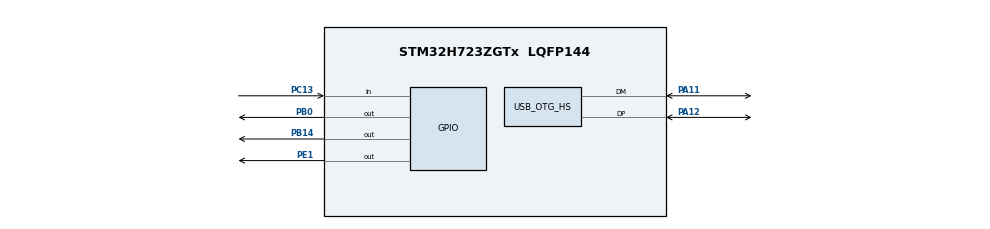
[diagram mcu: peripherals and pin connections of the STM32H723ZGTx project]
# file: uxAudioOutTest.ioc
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CORTEX_M7.AccessPermission_S-Cortex_Memory_Protection_Unit_Region2_Settings_S=MPU_REGION_FULL_ACCESS
CORTEX_M7.AccessPermission_S-Cortex_Memory_Protection_Unit_Region4_Settings_S=MPU_REGION_FULL_ACCESS
CORTEX_M7.AccessPermission_S-Cortex_Memory_Protection_Unit_Region5_Settings_S=MPU_REGION_FULL_ACCESS
CORTEX_M7.AccessPermission_S-Cortex_Memory_Protection_Unit_Region6_Settings_S=MPU_REGION_FULL_ACCESS
CORTEX_M7.BaseAddress_S-Cortex_Memory_Protection_Unit_Region2_Settings_S=0x24010000
CORTEX_M7.BaseAddress_S-Cortex_Memory_Protection_Unit_Region3_Settings_S=0x30000000
CORTEX_M7.BaseAddress_S-Cortex_Memory_Protection_Unit_Region4_Settings_S=0x38000000
CORTEX_M7.BaseAddress_S-Cortex_Memory_Protection_Unit_Region5_Settings_S=0x08000000
CORTEX_M7.BaseAddress_S-Cortex_Memory_Protection_Unit_Region6_Settings_S=0x40000000
CORTEX_M7.CPU_DCache=Enabled
CORTEX_M7.CPU_ICache=Enabled
CORTEX_M7.Enable_S-Cortex_Memory_Protection_Unit_Region1_Settings_S=__NULL
CORTEX_M7.Enable_S-Cortex_Memory_Protection_Unit_Region2_Settings_S=MPU_REGION_ENABLE
CORTEX_M7.Enable_S-Cortex_Memory_Protection_Unit_Region3_Settings_S=MPU_REGION_ENABLE
CORTEX_M7.Enable_S-Cortex_Memory_Protection_Unit_Region4_Settings_S=MPU_REGION_ENABLE
CORTEX_M7.Enable_S-Cortex_Memory_Protection_Unit_Region5_Settings_S=MPU_REGION_ENABLE
CORTEX_M7.Enable_S-Cortex_Memory_Protection_Unit_Region6_Settings_S=MPU_REGION_ENABLE
CORTEX_M7.IsBufferable_S-Cortex_Memory_Protection_Unit_Region6_Settings_S=MPU_ACCESS_BUFFERABLE
CORTEX_M7.IsCacheable_S-Cortex_Memory_Protection_Unit_Region5_Settings_S=MPU_ACCESS_CACHEABLE
CORTEX_M7.IsShareable_S-Cortex_Memory_Protection_Unit_Region2_Settings_S=MPU_ACCESS_NOT_SHAREABLE
CORTEX_M7.IsShareable_S-Cortex_Memory_Protection_Unit_Region3_Settings_S=MPU_ACCESS_SHAREABLE
CORTEX_M7.IsShareable_S-Cortex_Memory_Protection_Unit_Region4_Settings_S=MPU_ACCESS_SHAREABLE
CORTEX_M7.IsShareable_S-Cortex_Memory_Protection_Unit_Region6_Settings_S=MPU_ACCESS_SHAREABLE
CORTEX_M7.Size_S-Cortex_Memory_Protection_Unit_Region2_Settings_S=MPU_REGION_SIZE_64KB
CORTEX_M7.Size_S-Cortex_Memory_Protection_Unit_Region3_Settings_S=MPU_REGION_SIZE_32KB
CORTEX_M7.Size_S-Cortex_Memory_Protection_Unit_Region4_Settings_S=MPU_REGION_SIZE_16KB
CORTEX_M7.Size_S-Cortex_Memory_Protection_Unit_Region5_Settings_S=MPU_REGION_SIZE_1MB
CORTEX_M7.Size_S-Cortex_Memory_Protection_Unit_Region6_Settings_S=MPU_REGION_SIZE_512MB
CORTEX_M7.TypeExtField_S-Cortex_Memory_Protection_Unit_Region2_Settings_S=MPU_TEX_LEVEL1
CORTEX_M7.default_mode_Activation=1
Mcu.Family=STM32H7
Mcu.Name=STM32H723ZGTx
Mcu.Package=LQFP144
NUCLEO-H723ZG.BUTTON=1
NUCLEO-H723ZG.LD1=true
NUCLEO-H723ZG.LD2=true
NUCLEO-H723ZG.LD3=true
NUCLEO-H723ZG.VCP=true
NVIC.EXTI15_10_IRQn=true\:0\:0\:false\:false\:true\:false\:false\:true\:true
NVIC.OTG_HS_IRQn=true\:0\:0\:false\:false\:true\:false\:true\:true\:true
NVIC.PriorityGroup=NVIC_PRIORITYGROUP_4
NVIC.TIM1_UP_IRQn=true\:15\:0\:false\:false\:true\:false\:false\:true\:true
NVIC.TimeBase=TIM1_UP_IRQn
NVIC.TimeBaseIP=TIM1
PA11.Mode=Host_FS
PA11.Signal=USB_OTG_HS_DM
PA12.Mode=Host_FS
PA12.Signal=USB_OTG_HS_DP
PA13(JTMS/SWDIO).GPIO_Label=SWDIO
PA13(JTMS/SWDIO).Signal=DEBUG_JTMS-SWDIO
PA14(JTCK/SWCLK).GPIO_Label=SWCLK
PA14(JTCK/SWCLK).Signal=DEBUG_JTCK-SWCLK
PB0.Signal=GPIO_Output
PB14.Signal=GPIO_Output
PC13.Signal=GPIO_Input
PC14-OSC32_IN.Signal=RCC_OSC32_IN
PC15-OSC32_OUT.Signal=RCC_OSC32_OUT
PD8.Signal=USART3_TX
PD9.Signal=USART3_RX
PE1.Signal=GPIO_Output
PH0-OSC_IN.Mode=HSE-External-Clock-Source
PH0-OSC_IN.Signal=RCC_OSC_IN
ProjectManager.HeapSize=0x200
ProjectManager.StackSize=0x400
ProjectManager.TargetToolchain=CMake
RCC.ADCFreq_Value=76000000
RCC.APB1Freq_Value=137500000
RCC.APB2Freq_Value=137500000
RCC.APB3Freq_Value=137500000
RCC.APB4Freq_Value=137500000
RCC.CortexFreq_Value=550000000
RCC.D1PPRE=RCC_APB3_DIV2
RCC.D2PPRE1=RCC_APB1_DIV2
RCC.D2PPRE2=RCC_APB2_DIV2
RCC.D3PPRE=RCC_APB4_DIV2
RCC.DIVM1=1
RCC.DIVM2=1
RCC.DIVN1=68
RCC.DIVN2=19
RCC.DIVP1=1
RCC.DIVQ1=4
RCC.HCLKFreq_Value=275000000
RCC.HPRE=RCC_HCLK_DIV2
RCC.HSE_VALUE=8000000
RCC.PLLFRACN=6144
RCC.PLLSourceVirtual=RCC_PLLSOURCE_HSE
RCC.SYSCLKFreq_VALUE=550000000
RCC.SYSCLKSource=RCC_SYSCLKSOURCE_PLLCLK
RCC.USBCLockSelection=RCC_USBCLKSOURCE_HSI48
RCC.USBFreq_Value=48000000
STMicroelectronics.X-CUBE-AZRTOS-H7.3.4.0.REG_UX_HOST_CORE=true
STMicroelectronics.X-CUBE-AZRTOS-H7.3.4.0.REG_UX_Host_THREAD=1
STMicroelectronics.X-CUBE-AZRTOS-H7.3.4.0.TX_APP_CREATION=1
STMicroelectronics.X-CUBE-AZRTOS-H7.3.4.0.TX_APP_GENERATE_INIT_CODE=true
STMicroelectronics.X-CUBE-AZRTOS-H7.3.4.0.TX_APP_MEM_POOL_SIZE=40*1024
STMicroelectronics.X-CUBE-AZRTOS-H7.3.4.0.TX_APP_STACK_SIZE=1024
STMicroelectronics.X-CUBE-AZRTOS-H7.3.4.0.ThreadXCcRTOSJjThreadXJjCore=true
STMicroelectronics.X-CUBE-AZRTOS-H7.3.4.0.USBXCcUSBJjUSBXJjCoreSystem=true
STMicroelectronics.X-CUBE-AZRTOS-H7.3.4.0.USBXCcUSBJjUSBXJjUXOoHostOoClassOoAUDIO=true
STMicroelectronics.X-CUBE-AZRTOS-H7.3.4.0.USBXCcUSBJjUSBXJjUXOoHostOoControllers=true
STMicroelectronics.X-CUBE-AZRTOS-H7.3.4.0.USBXCcUSBJjUSBXJjUXOoHostOoCoreStack=true
STMicroelectronics.X-CUBE-AZRTOS-H7.3.4.0.USBX_HOST_SYS_SIZE=20*1024
STMicroelectronics.X-CUBE-AZRTOS-H7.3.4.0.UX_HOST_APP_MEM_POOL_SIZE=32*1024
STMicroelectronics.X-CUBE-AZRTOS-H7.3.4.0.UX_HOST_CLASS_AUDIO_2_SUPPORT=1
STMicroelectronics.X-CUBE-AZRTOS-H7.3.4.0.UX_HOST_CLASS_AUDIO_FEEDBACK_SUPPORT=1
STMicroelectronics.X-CUBE-AZRTOS-H7.3.4.0.UX_MAX_HCD=2
STMicroelectronics.X-CUBE-AZRTOS-H7.3.4.0_IsAnAzureRtosMw=true
USB_OTG_HS.VirtualMode-Host_FS=Host_FS
USB_OTG_HS.dma_enable-Host_FS=ENABLE
VP_MEMORYMAP_VS_MEMORYMAP.Mode=CurAppReg
VP_NUCLEO-H723ZG_VS_BSP_COMMON.Mode=COMMON
VP_STMicroelectronics.X-CUBE-AZRTOS-H7_VS_RTOSJjThreadX_6.4.0_3.4.0.Mode=RTOSJjThreadX
VP_STMicroelectronics.X-CUBE-AZRTOS-H7_VS_USBJjUSBX_6.4.0_3.4.0.Mode=USBJjUSBX
VP_SYS_VS_tim1.Mode=TIM1
board=NUCLEO-H723ZG

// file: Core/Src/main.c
/* USER CODE BEGIN Header */
/**
  ******************************************************************************
  * @file           : main.c
  * @brief          : Main program body
  ******************************************************************************
  * @attention
  *
  * Copyright (c) 2025 STMicroelectronics.
  * All rights reserved.
  *
  * This software is licensed under terms that can be found in the LICENSE file
  * in the root directory of this software component.
  * If no LICENSE file comes with this software, it is provided AS-IS.
  *
  ******************************************************************************
  */
/* USER CODE END Header */
#include "app_threadx.h"
#include "main.h"
#include "gpio.h"

COM_InitTypeDef BspCOMInit;

void SystemClock_Config(void);
static void MPU_Config(void);

int main(void)
{

  /* MPU Configuration--------------------------------------------------------*/
  MPU_Config();

  /* Enable the CPU Cache */

  /* Enable I-Cache---------------------------------------------------------*/
  SCB_EnableICache();

  /* Enable D-Cache---------------------------------------------------------*/
  SCB_EnableDCache();

  /* MCU Configuration--------------------------------------------------------*/

  /* Reset of all peripherals, Initializes the Flash interface and the Systick. */
  HAL_Init();

  /* Configure the system clock */
  SystemClock_Config();

  /* Initialize all configured peripherals */
  MX_GPIO_Init();

  /* Initialize leds */
  BSP_LED_Init(LED_GREEN);
  BSP_LED_Init(LED_YELLOW);
  BSP_LED_Init(LED_RED);

  /* Initialize USER push-button, will be used to trigger an interrupt each time it's pressed.*/
  BSP_PB_Init(BUTTON_USER, BUTTON_MODE_EXTI);

  /* Initialize COM1 port (115200, 8 bits (7-bit data + 1 stop bit), no parity */
  BspCOMInit.BaudRate   = 115200;
  BspCOMInit.WordLength = COM_WORDLENGTH_8B;
  BspCOMInit.StopBits   = COM_STOPBITS_1;
  BspCOMInit.Parity     = COM_PARITY_NONE;
  BspCOMInit.HwFlowCtl  = COM_HWCONTROL_NONE;
  if (BSP_COM_Init(COM1, &BspCOMInit) != BSP_ERROR_NONE)
  {
    Error_Handler();
  }

  MX_ThreadX_Init();

  /* We should never get here as control is now taken by the scheduler */

  /* Infinite loop */
  while (1)
  {

  }
}

void SystemClock_Config(void)
{
  RCC_OscInitTypeDef RCC_OscInitStruct = {0};
  RCC_ClkInitTypeDef RCC_ClkInitStruct = {0};

  /** Supply configuration update enable
  */
  HAL_PWREx_ConfigSupply(PWR_LDO_SUPPLY);

  /** Configure the main internal regulator output voltage
  */
  __HAL_PWR_VOLTAGESCALING_CONFIG(PWR_REGULATOR_VOLTAGE_SCALE0);

  while(!__HAL_PWR_GET_FLAG(PWR_FLAG_VOSRDY)) {}

  /** Initializes the RCC Oscillators according to the specified parameters
  * in the RCC_OscInitTypeDef structure.
  */
  RCC_OscInitStruct.OscillatorType = RCC_OSCILLATORTYPE_HSI48|RCC_OSCILLATORTYPE_HSE;
  RCC_OscInitStruct.HSEState = RCC_HSE_BYPASS;
  RCC_OscInitStruct.HSI48State = RCC_HSI48_ON;
  RCC_OscInitStruct.PLL.PLLState = RCC_PLL_ON;
  RCC_OscInitStruct.PLL.PLLSource = RCC_PLLSOURCE_HSE;
  RCC_OscInitStruct.PLL.PLLM = 1;
  RCC_OscInitStruct.PLL.PLLN = 68;
  RCC_OscInitStruct.PLL.PLLP = 1;
  RCC_OscInitStruct.PLL.PLLQ = 4;
  RCC_OscInitStruct.PLL.PLLR = 2;
  RCC_OscInitStruct.PLL.PLLRGE = RCC_PLL1VCIRANGE_3;
  RCC_OscInitStruct.PLL.PLLVCOSEL = RCC_PLL1VCOWIDE;
  RCC_OscInitStruct.PLL.PLLFRACN = 6144;
  if (HAL_RCC_OscConfig(&RCC_OscInitStruct) != HAL_OK)
  {
    Error_Handler();
  }

  /** Initializes the CPU, AHB and APB buses clocks
  */
  RCC_ClkInitStruct.ClockType = RCC_CLOCKTYPE_HCLK|RCC_CLOCKTYPE_SYSCLK
                              |RCC_CLOCKTYPE_PCLK1|RCC_CLOCKTYPE_PCLK2
                              |RCC_CLOCKTYPE_D3PCLK1|RCC_CLOCKTYPE_D1PCLK1;
  RCC_ClkInitStruct.SYSCLKSource = RCC_SYSCLKSOURCE_PLLCLK;
  RCC_ClkInitStruct.SYSCLKDivider = RCC_SYSCLK_DIV1;
  RCC_ClkInitStruct.AHBCLKDivider = RCC_HCLK_DIV2;
  RCC_ClkInitStruct.APB3CLKDivider = RCC_APB3_DIV2;
  RCC_ClkInitStruct.APB1CLKDivider = RCC_APB1_DIV2;
  RCC_ClkInitStruct.APB2CLKDivider = RCC_APB2_DIV2;
  RCC_ClkInitStruct.APB4CLKDivider = RCC_APB4_DIV2;

  if (HAL_RCC_ClockConfig(&RCC_ClkInitStruct, FLASH_LATENCY_3) != HAL_OK)
  {
    Error_Handler();
  }
}

 /* MPU Configuration */

void MPU_Config(void)
{
  MPU_Region_InitTypeDef MPU_InitStruct = {0};

  /* Disables the MPU */
  HAL_MPU_Disable();

  /** Initializes and configures the Region and the memory to be protected
  */
  MPU_InitStruct.Enable = MPU_REGION_ENABLE;
  MPU_InitStruct.Number = MPU_REGION_NUMBER0;
  MPU_InitStruct.BaseAddress = 0x0;
  MPU_InitStruct.Size = MPU_REGION_SIZE_4GB;
  MPU_InitStruct.SubRegionDisable = 0x87;
  MPU_InitStruct.TypeExtField = MPU_TEX_LEVEL0;
  MPU_InitStruct.AccessPermission = MPU_REGION_NO_ACCESS;
  MPU_InitStruct.DisableExec = MPU_INSTRUCTION_ACCESS_DISABLE;
  MPU_InitStruct.IsShareable = MPU_ACCESS_SHAREABLE;
  MPU_InitStruct.IsCacheable = MPU_ACCESS_NOT_CACHEABLE;
  MPU_InitStruct.IsBufferable = MPU_ACCESS_NOT_BUFFERABLE;

  HAL_MPU_ConfigRegion(&MPU_InitStruct);

  /** Initializes and configures the Region and the memory to be protected
  */
  MPU_InitStruct.Number = MPU_REGION_NUMBER2;
  MPU_InitStruct.BaseAddress = 0x24010000;
  MPU_InitStruct.Size = MPU_REGION_SIZE_64KB;
  MPU_InitStruct.SubRegionDisable = 0x0;
  MPU_InitStruct.TypeExtField = MPU_TEX_LEVEL1;
  MPU_InitStruct.AccessPermission = MPU_REGION_FULL_ACCESS;
  MPU_InitStruct.DisableExec = MPU_INSTRUCTION_ACCESS_ENABLE;
  MPU_InitStruct.IsShareable = MPU_ACCESS_NOT_SHAREABLE;

  HAL_MPU_ConfigRegion(&MPU_InitStruct);

  /** Initializes and configures the Region and the memory to be protected
  */
  MPU_InitStruct.Number = MPU_REGION_NUMBER3;
  MPU_InitStruct.BaseAddress = 0x30000000;
  MPU_InitStruct.Size = MPU_REGION_SIZE_32KB;
  MPU_InitStruct.TypeExtField = MPU_TEX_LEVEL0;
  MPU_InitStruct.AccessPermission = MPU_REGION_NO_ACCESS;
  MPU_InitStruct.IsShareable = MPU_ACCESS_SHAREABLE;

  HAL_MPU_ConfigRegion(&MPU_InitStruct);

  /** Initializes and configures the Region and the memory to be protected
  */
  MPU_InitStruct.Number = MPU_REGION_NUMBER4;
  MPU_InitStruct.BaseAddress = 0x38000000;
  MPU_InitStruct.Size = MPU_REGION_SIZE_16KB;
  MPU_InitStruct.AccessPermission = MPU_REGION_FULL_ACCESS;

  HAL_MPU_ConfigRegion(&MPU_InitStruct);

  /** Initializes and configures the Region and the memory to be protected
  */
  MPU_InitStruct.Number = MPU_REGION_NUMBER5;
  MPU_InitStruct.BaseAddress = 0x08000000;
  MPU_InitStruct.Size = MPU_REGION_SIZE_1MB;
  MPU_InitStruct.IsShareable = MPU_ACCESS_NOT_SHAREABLE;
  MPU_InitStruct.IsCacheable = MPU_ACCESS_CACHEABLE;

  HAL_MPU_ConfigRegion(&MPU_InitStruct);

  /** Initializes and configures the Region and the memory to be protected
  */
  MPU_InitStruct.Number = MPU_REGION_NUMBER6;
  MPU_InitStruct.BaseAddress = 0x40000000;
  MPU_InitStruct.Size = MPU_REGION_SIZE_512MB;
  MPU_InitStruct.IsShareable = MPU_ACCESS_SHAREABLE;
  MPU_InitStruct.IsCacheable = MPU_ACCESS_NOT_CACHEABLE;
  MPU_InitStruct.IsBufferable = MPU_ACCESS_BUFFERABLE;

  HAL_MPU_ConfigRegion(&MPU_InitStruct);
  /* Enables the MPU */
  HAL_MPU_Enable(MPU_PRIVILEGED_DEFAULT);

}

void HAL_TIM_PeriodElapsedCallback(TIM_HandleTypeDef *htim)
{
  if (htim->Instance == TIM1)
  {
    HAL_IncTick();
  }
}

void Error_Handler(void)
{
  /* USER CODE BEGIN Error_Handler_Debug */
  /* User can add his own implementation to report the HAL error return state */
  __disable_irq();
  BSP_LED_On(LED_RED);
  while (1)
  {
  }
  /* USER CODE END Error_Handler_Debug */
}
